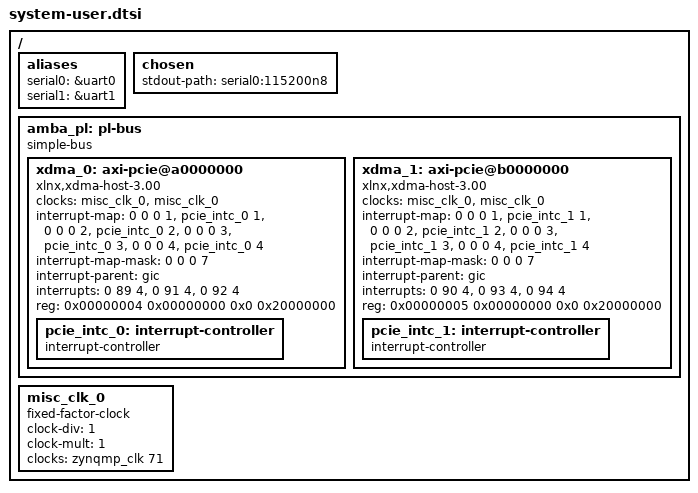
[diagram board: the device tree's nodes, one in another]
/*
 * FPGA Drive FMC reference design DT overlay for ZCU111 (EDF flow).
 *
 * 2x xilinx_xdma 4-lane Root Ports for the dual M.2 sockets on the FPGA
 * Drive FMC at FMCP. The bbappend selects the per-target file via
 * FPGADRV_TARGET (see device-tree.bbappend).
 *
 * The SoC-side hardware (cortexa53, uart, gem, sdhci, etc.) is described
 * by the AMD-validated cortexa53-linux.dts in meta-amd-adaptive-socs-bsp.
 * This file is appended to that DT (via EXTRA_DT_INCLUDE_FILES) to add
 * the FPGA Drive PL hardware — two xilinx_xdma PCIe Root Complex
 * controllers wired to GIC interrupts.
 *
 * The xdma_0 / xdma_1 nodes here were generated by `xsct hsi::generate_target`
 * against Vivado/zcu111/fpgadrv_wrapper.xsa using device-tree-xlnx
 * (xlnx_rel_v2025.2). When the Vivado BD changes, regenerate by running:
 *
 *   xsct -eval "hsi::open_hw_design <xsa>; \
 *               hsi::set_repo_path <device-tree-xlnx>; \
 *               hsi::create_sw_design device-tree -os device_tree \
 *                   -proc psu_cortexa53_0; \
 *               hsi::generate_target -dir /tmp/dtg_out"
 *
 * and copy /tmp/dtg_out/pl.dtsi's pl-bus contents over the block below.
 *
 * Aliases override gen-machineconf's port-number heuristic and pin stdout
 * to UART0 (the silkscreened "UART 0" on the ZCU111).
 */

/ {
   aliases {
      serial0 = &uart0;
      serial1 = &uart1;
   };
   chosen {
      stdout-path = "serial0:115200n8";
   };

   amba_pl: pl-bus {
      #address-cells = <2>;
      #size-cells = <2>;
      compatible = "simple-bus";
      ranges;

      xdma_0: axi-pcie@a0000000 {
         #address-cells = <3>;
         #interrupt-cells = <1>;
         #size-cells = <2>;
         clock-names = "sys_clk", "sys_clk_gt";
         clocks = <&misc_clk_0>, <&misc_clk_0>;
         compatible = "xlnx,xdma-host-3.00";
         device_type = "pci";
         interrupt-map = <0 0 0 1 &pcie_intc_0 1>,
                         <0 0 0 2 &pcie_intc_0 2>,
                         <0 0 0 3 &pcie_intc_0 3>,
                         <0 0 0 4 &pcie_intc_0 4>;
         interrupt-map-mask = <0 0 0 7>;
         interrupt-names = "misc", "msi0", "msi1";
         interrupt-parent = <&gic>;
         interrupts = <0 89 4>, <0 91 4>, <0 92 4>;
         ranges = <0x02000000 0x00000000 0xA0000000 0x0 0xA0000000 0x00000000 0x10000000>;
         reg = <0x00000004 0x00000000 0x0 0x20000000>;
         pcie_intc_0: interrupt-controller {
            #address-cells = <0>;
            #interrupt-cells = <1>;
            interrupt-controller;
         };
      };

      xdma_1: axi-pcie@b0000000 {
         #address-cells = <3>;
         #interrupt-cells = <1>;
         #size-cells = <2>;
         clock-names = "sys_clk", "sys_clk_gt";
         clocks = <&misc_clk_0>, <&misc_clk_0>;
         compatible = "xlnx,xdma-host-3.00";
         device_type = "pci";
         interrupt-map = <0 0 0 1 &pcie_intc_1 1>,
                         <0 0 0 2 &pcie_intc_1 2>,
                         <0 0 0 3 &pcie_intc_1 3>,
                         <0 0 0 4 &pcie_intc_1 4>;
         interrupt-map-mask = <0 0 0 7>;
         interrupt-names = "misc", "msi0", "msi1";
         interrupt-parent = <&gic>;
         interrupts = <0 90 4>, <0 93 4>, <0 94 4>;
         ranges = <0x02000000 0x00000000 0xB0000000 0x0 0xB0000000 0x00000000 0x10000000>;
         reg = <0x00000005 0x00000000 0x0 0x20000000>;
         pcie_intc_1: interrupt-controller {
            #address-cells = <0>;
            #interrupt-cells = <1>;
            interrupt-controller;
         };
      };
   };

   misc_clk_0: misc_clk_0 {
      #clock-cells = <0>;
      clock-div = <1>;
      clock-mult = <1>;
      clocks = <&zynqmp_clk 71>;
      compatible = "fixed-factor-clock";
   };
};
